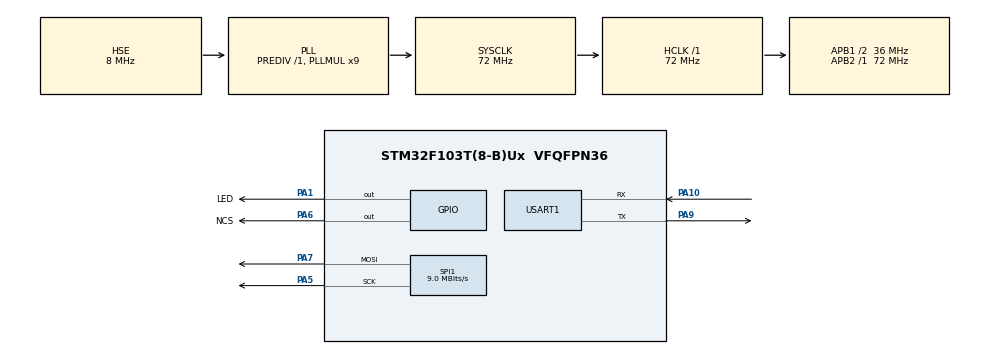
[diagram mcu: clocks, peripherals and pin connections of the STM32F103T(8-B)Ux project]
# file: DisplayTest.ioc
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Dma.Request0=SPI1_TX
Dma.SPI1_TX.0.Direction=DMA_MEMORY_TO_PERIPH
Dma.SPI1_TX.0.Instance=DMA1_Channel3
Dma.SPI1_TX.0.MemDataAlignment=DMA_MDATAALIGN_HALFWORD
Dma.SPI1_TX.0.MemInc=DMA_MINC_ENABLE
Dma.SPI1_TX.0.Mode=DMA_NORMAL
Dma.SPI1_TX.0.PeriphDataAlignment=DMA_PDATAALIGN_HALFWORD
Dma.SPI1_TX.0.PeriphInc=DMA_PINC_DISABLE
Dma.SPI1_TX.0.Priority=DMA_PRIORITY_LOW
FREERTOS.Tasks01=mainTask,24,128,mainTaskFunc,As weak,NULL,Static,mainTaskBuffer,mainTaskControlBlock
Mcu.Family=STM32F1
Mcu.Name=STM32F103T(8-B)Ux
Mcu.Package=VFQFPN36
NVIC.DMA1_Channel3_IRQn=true\:5\:0\:false\:false\:true\:true\:false\:true
NVIC.PriorityGroup=NVIC_PRIORITYGROUP_4
NVIC.TIM1_UP_IRQn=true\:0\:0\:false\:false\:true\:false\:false\:true
NVIC.TimeBase=TIM1_UP_IRQn
NVIC.TimeBaseIP=TIM1
PA1.GPIO_Label=LED
PA1.Signal=GPIO_Output
PA10.Mode=Asynchronous
PA10.Signal=USART1_RX
PA13.Mode=Serial_Wire
PA13.Signal=SYS_JTMS-SWDIO
PA14.Mode=Serial_Wire
PA14.Signal=SYS_JTCK-SWCLK
PA5.Mode=TX_Only_Simplex_Unidirect_Master
PA5.Signal=SPI1_SCK
PA6.GPIO_Label=NCS
PA6.Signal=GPIO_Output
PA7.Mode=TX_Only_Simplex_Unidirect_Master
PA7.Signal=SPI1_MOSI
PA9.Mode=Asynchronous
PA9.Signal=USART1_TX
PD0-OSC_IN.Mode=HSE-External-Oscillator
PD0-OSC_IN.Signal=RCC_OSC_IN
PD1-OSC_OUT.Mode=HSE-External-Oscillator
PD1-OSC_OUT.Signal=RCC_OSC_OUT
ProjectManager.HeapSize=0x200
ProjectManager.StackSize=0x400
ProjectManager.TargetToolchain=STM32CubeIDE
RCC.AHBFreq_Value=72000000
RCC.APB1CLKDivider=RCC_HCLK_DIV2
RCC.APB1Freq_Value=36000000
RCC.APB1TimFreq_Value=72000000
RCC.APB2Freq_Value=72000000
RCC.APB2TimFreq_Value=72000000
RCC.HCLKFreq_Value=72000000
RCC.PLLMUL=RCC_PLL_MUL9
RCC.PLLSourceVirtual=RCC_PLLSOURCE_HSE
RCC.SYSCLKFreq_VALUE=72000000
RCC.SYSCLKSource=RCC_SYSCLKSOURCE_PLLCLK
RCC.USBFreq_Value=72000000
SPI1.BaudRatePrescaler=SPI_BAUDRATEPRESCALER_8
SPI1.CalculateBaudRate=9.0 MBits/s
SPI1.DataSize=SPI_DATASIZE_16BIT
SPI1.Direction=SPI_DIRECTION_2LINES
SPI1.Mode=SPI_MODE_MASTER
SPI1.VirtualType=VM_MASTER
USART1.VirtualMode=VM_ASYNC
VP_FREERTOS_VS_CMSIS_V2.Mode=CMSIS_V2
VP_SYS_VS_tim1.Mode=TIM1
board=custom

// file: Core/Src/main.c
/* USER CODE BEGIN Header */
/**
 ******************************************************************************
 * @file           : main.c
 * @brief          : Main program body
 ******************************************************************************
 * @attention
 *
 * <h2><center>&copy; Copyright (c) 2020 STMicroelectronics.
 * All rights reserved.</center></h2>
 *
 * This software component is licensed by ST under BSD 3-Clause license,
 * the "License"; You may not use this file except in compliance with the
 * License. You may obtain a copy of the License at:
 *                        opensource.org/licenses/BSD-3-Clause
 *
 ******************************************************************************
 */
/* USER CODE END Header */

#include "main.h"
#include "cmsis_os.h"
#include "dma.h"
#include "spi.h"
#include "usart.h"
#include "gpio.h"

void SystemClock_Config(void);
void MX_FREERTOS_Init(void);

int main(void)
{

  /* MCU Configuration--------------------------------------------------------*/

  /* Reset of all peripherals, Initializes the Flash interface and the Systick. */
  HAL_Init();

  /* Configure the system clock */
  SystemClock_Config();

  /* Initialize all configured peripherals */
  MX_GPIO_Init();
  MX_DMA_Init();
  MX_SPI1_Init();
  MX_USART1_UART_Init();

  /* Init scheduler */
  osKernelInitialize();  /* Call init function for freertos objects (in freertos.c) */
  MX_FREERTOS_Init();
  /* Start scheduler */
  osKernelStart();

  /* We should never get here as control is now taken by the scheduler */
  /* Infinite loop */
	while (1) {

    /* USER CODE BEGIN 3 */
		__WFE();
	}
  /* USER CODE END 3 */
}

void SystemClock_Config(void)
{
  RCC_OscInitTypeDef RCC_OscInitStruct = {0};
  RCC_ClkInitTypeDef RCC_ClkInitStruct = {0};

  /** Initializes the CPU, AHB and APB busses clocks
  */
  RCC_OscInitStruct.OscillatorType = RCC_OSCILLATORTYPE_HSE;
  RCC_OscInitStruct.HSEState = RCC_HSE_ON;
  RCC_OscInitStruct.HSEPredivValue = RCC_HSE_PREDIV_DIV1;
  RCC_OscInitStruct.HSIState = RCC_HSI_ON;
  RCC_OscInitStruct.PLL.PLLState = RCC_PLL_ON;
  RCC_OscInitStruct.PLL.PLLSource = RCC_PLLSOURCE_HSE;
  RCC_OscInitStruct.PLL.PLLMUL = RCC_PLL_MUL9;
  if (HAL_RCC_OscConfig(&RCC_OscInitStruct) != HAL_OK)
  {
    Error_Handler();
  }
  /** Initializes the CPU, AHB and APB busses clocks
  */
  RCC_ClkInitStruct.ClockType = RCC_CLOCKTYPE_HCLK|RCC_CLOCKTYPE_SYSCLK
                              |RCC_CLOCKTYPE_PCLK1|RCC_CLOCKTYPE_PCLK2;
  RCC_ClkInitStruct.SYSCLKSource = RCC_SYSCLKSOURCE_PLLCLK;
  RCC_ClkInitStruct.AHBCLKDivider = RCC_SYSCLK_DIV1;
  RCC_ClkInitStruct.APB1CLKDivider = RCC_HCLK_DIV2;
  RCC_ClkInitStruct.APB2CLKDivider = RCC_HCLK_DIV1;

  if (HAL_RCC_ClockConfig(&RCC_ClkInitStruct, FLASH_LATENCY_2) != HAL_OK)
  {
    Error_Handler();
  }
}

 /**
  * @brief  Period elapsed callback in non blocking mode
  * @note   This function is called  when TIM1 interrupt took place, inside
  * HAL_TIM_IRQHandler(). It makes a direct call to HAL_IncTick() to increment
  * a global variable "uwTick" used as application time base.
  * @param  htim : TIM handle
  * @retval None
  */
void HAL_TIM_PeriodElapsedCallback(TIM_HandleTypeDef *htim)
{
  if (htim->Instance == TIM1) {
    HAL_IncTick();
  }
}

void Error_Handler(void)
{
}

/************************ (C) COPYRIGHT STMicroelectronics *****END OF FILE****/

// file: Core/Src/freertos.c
/* USER CODE BEGIN Header */
/**
  ******************************************************************************
  * File Name          : freertos.c
  * Description        : Code for freertos applications
  ******************************************************************************
  * @attention
  *
  * <h2><center>&copy; Copyright (c) 2020 STMicroelectronics.
  * All rights reserved.</center></h2>
  *
  * This software component is licensed by ST under Ultimate Liberty license
  * SLA0044, the "License"; You may not use this file except in compliance with
  * the License. You may obtain a copy of the License at:
  *                             www.st.com/SLA0044
  *
  ******************************************************************************
  */
/* USER CODE END Header */

#include "FreeRTOS.h"
#include "task.h"
#include "main.h"
#include "cmsis_os.h"

typedef StaticTask_t osStaticThreadDef_t;

/* Definitions for mainTask */
osThreadId_t mainTaskHandle;
uint32_t mainTaskBuffer[ 128 ];
osStaticThreadDef_t mainTaskControlBlock;
const osThreadAttr_t mainTask_attributes = {
  .name = "mainTask",
  .stack_mem = &mainTaskBuffer[0],
  .stack_size = sizeof(mainTaskBuffer),
  .cb_mem = &mainTaskControlBlock,
  .cb_size = sizeof(mainTaskControlBlock),
  .priority = (osPriority_t) osPriorityNormal,
};

void mainTaskFunc(void *argument);

void MX_FREERTOS_Init(void); /* (MISRA C 2004 rule 8.1) */

void MX_FREERTOS_Init(void) {

  /* Create the thread(s) */
  /* creation of mainTask */
  mainTaskHandle = osThreadNew(mainTaskFunc, NULL, &mainTask_attributes);

}

__weak void mainTaskFunc(void *argument)
{
  for(;;)
  {
    osDelay(1);
  }
}

/************************ (C) COPYRIGHT STMicroelectronics *****END OF FILE****/
